# EOS-S3 register map
File version: 0.1
CPU: CM4 r0p1, selectable endian, MPU, FPU, 3 interrupt priority bits
Registers are 32-bit, read-write, reset 0x0 unless marked. A register's access mark holds for its fields unless they carry their own. Offsets are from the block's base; [hi:lo] are bit positions; {n}, {i} and the like mark numbered series.

## SPT — Simple Periodic Timer
Base 0x40005C00
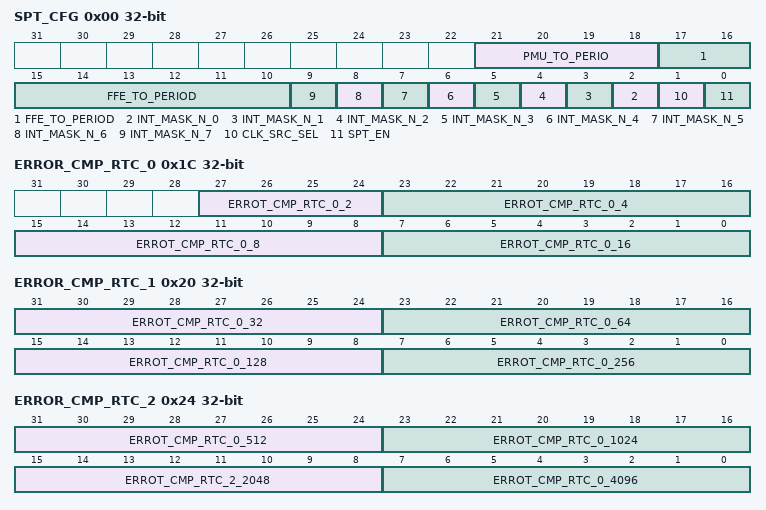
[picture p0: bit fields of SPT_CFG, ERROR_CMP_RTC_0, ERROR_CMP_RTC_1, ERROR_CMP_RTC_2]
0x00 SPT_CFG — Configuration register for the simple periodic timer
  [21:18] PMU_TO_PERIO — PMU Kick Off (Time out Period) Configuration PMU Kick Off signal will assert N cycles (value in field) before FFE kick signal asserting. NOTE : For 0x0, FFE Time out Event will be used to wake up FFE power domain.
  [17:10] FFE_TO_PERIOD — FFE Kick Off (timeout) perdiod configuration (value in registers = period, max value is 100). NOTE : If 0x0, The Event Counter will be turn off and all the Signals to PMU will be de-asserted. NOTE : If PMU_TO_PERIOD is 0x0, FFE Kick off signal will not trigger until FFE is alive.
  [n+2] INT_MASK_N_{n} (n=0..7) — Activate or deactive interrupt trigger signal {n}
    0=Unmask the interrupt; 1=Mask the interrupt
  [1] CLK_SRC_SEL — Select the clock source
    0=clock_32khz (Clock source is 32KHz); 1=clock_16khz (Clock source is 16KHz)
  [0] SPT_EN — Field to enable the timer/counter
    0=disable (Except 30 bits Timer, all the counter will be reset to 0.); 1=enable (Turn on Counter/Timer)
0x04 SLEEP_MODE — Allows blocking the PMU and FFE kickoff signal
  [0] SLEEP_MODE — If set, the PMU and FFE kick off signal will be blocked. This bit will be cleared by HW if any of non-Mask INT triggered
0x08 ERROR_CMP_40M — 40 msec increment error compensation register
  [19:0] ERROR_CMP_40M — Each 40ms period contains sub-events. For each sub-event, you can add 1ms when it triggers. Theres a sub-event every odd number, with each bit of this field corresponding to that event, so: [bit 0 = 1st ms event, bit 1 = 3rd ms event ... bit 19 = 39th ms event]
0x0C ERROR_CMP_1S_0 — 1 sec Increment Error Compensation 0 Register
  [31:0] ERROR_CMP_1S_0 — Each 1s period contains sub-events for every 40ms counted, and a subevent for the first ms counted. Each bit-pair in this field corresponds to one of those sub-events. Values of 0 or 2 in bit pairs do nothing. A value of 3 means the counter should decrease 1ms everytime the subevent is triggered, and a value of 1 means the counter should increment 1ms every time the event is triggered. [bits 1:0 = 1st 1ms event, bit 3:2 = 1st 40ms event ... 31:30 = 15th 40ms event]
0x10 ERROR_CMP_1S_1 — 1 sec Incremente Error Compensation 1 Register
  [17:0] ERROR_CMP_1S_1 — Each 1s period contains sub-events for every 40ms counted. Each bit-pair in this field corresponds to one of those sub-events. Values of 0 or 2 in bit pairs do nothing. A value of 3 means the counter should decrease 1ms everytime the sub-event is triggered, and a value of 1 means the counter should increment 1ms every time the event is triggered. Starts from the 16th 40ms event. [bits 1:0 = 16st 40ms event, bit 3:2 = 17st 40ms event ... 17:16 = 24th 40ms event]
0x14 ERROR_CMP_1S_2 — 1 sec Incremente Error Compensation 2 Register
  [23:0] ERROR_CMP_1S_2 — Each 1s period contains sub-events for every 80ms counted. Each bit-pair in this field corresponds to one of those sub-events. Values of 0 or 2 in bit pairs do nothing. A value of 3 means the counter should decrease 1ms everytime the sub-event is triggered, and a value of 1 means the counter should increment 1ms every time the event is triggered. [bits 1:0 = 1st 80ms event, bit 3:2 = 2nd 80ms event ... 23:22 = 12th 80ms event]
0x18 ERROR_CMP_1S_3 — 1 sec Incremente Error Compensation 3 Register
  [11:0] ERROR_CMP_1S_3 — Each 1s period contains sub-events for every 150ms counted. Each bit-pair in this field corresponds to one of those sub-events. Values of 0 or 2 in bit pairs do nothing. A value of 3 means the counter should decrease 1ms everytime the sub-event is triggered, and a value of 1 means the counter should increment 1ms every time the event is triggered. [bits 1:0 = 1st 150ms event, bit 3:2 = 2nd 150ms event ... 11:10 = 6th 150ms event]
0x1C ERROR_CMP_RTC_0 — 2, 4, 6, 8, 16 sec Increment Error Compensation Register
  [27:24] ERROT_CMP_RTC_0_2 — Every 2s there are 2 sub-events. Each bit pair in this field corresponds to those sub-events. Values of 0 and 2 do nothing. A value of 3 means the counter should decrement 1ms, and a value of 1 means the counter must add 1ms. [bits 25:24 1002ms event, bits 27:26 1450ms event]
  [23:16] ERROT_CMP_RTC_0_4 — Every 4s there are 4 sub-events. Each bit pair in this field corresponds to those sub-events. Values of 0 and 2 do nothing. A value of 3 means the counter should decrement 1ms, and a value of 1 means the counter must add 1ms. [bits 17:16 2002ms event, bits 19:18 2450ms event, bits 21:20 3002ms event, bits 23:22 3450ms event]
  [15:8] ERROT_CMP_RTC_0_8 — Every 8s there are 4 sub-events. Each bit pair in this field corresponds to those sub-events. Values of 0 and 2 do nothing. A value of 3 means the counter should decrement 1ms, and a value of 1 means the counter must add 1ms. [bits 9:8 4002ms event, bits 11:10 4450ms event, bits 13:12 6002ms event, bits 15:14 6450ms event]
  [7:0] ERROT_CMP_RTC_0_16 — Every 16s there are 4 sub-events. Each bit pair in this field corresponds to those sub-events. Values of 0 and 2 do nothing. A value of 3 means the counter should decrement 1ms, and a value of 1 means the counter must add 1ms. [bits 1:0 4002ms event, bits 3:2 4450ms event, bits 5:4 6002ms event, bits 7:6 6450ms event]
0x20 ERROR_CMP_RTC_1 — 32, 64, 128, 256 sec Increment Error Compensation Register
  [31:24] ERROT_CMP_RTC_0_32 — Every 32s there are 4 sub-events. Each bit pair in this field corresponds to those sub-events. Values of 0 and 2 do nothing. A value of 3 means the counter should decrement 1ms, and a value of 1 means the counter must add 1ms. [bits 25:24 16002ms event, bits 27:26 16450ms event, bits 29:28 24450 event, bits 31:30 24450 event]
  [23:16] ERROT_CMP_RTC_0_64 — Every 64s there are 4 sub-events. Each bit pair in this field corresponds to those sub-events. Values of 0 and 2 do nothing. A value of 3 means the counter should decrement 1ms, and a value of 1 means the counter must add 1ms. [bits 17:16 32002ms event, bits 19:18 32450ms event, bits 21:20 48002ms event, bits 23:22 48450ms event]
  [15:8] ERROT_CMP_RTC_0_128 — Every 128s there are 4 sub-events. Each bit pair in this field corresponds to those sub-events. Values of 0 and 2 do nothing. A value of 3 means the counter should decrement 1ms, and a value of 1 means the counter must add 1ms. [bits 9:8 64002ms event, bits 11:10 64450ms event, bits 13:12 96002ms event, bits 15:14 96450ms event]
  [7:0] ERROT_CMP_RTC_0_256 — Every 256s there are 4 sub-events. Each bit pair in this field corresponds to those sub-events. Values of 0 and 2 do nothing. A value of 3 means the counter should decrement 1ms, and a value of 1 means the counter must add 1ms. [bits 1:0 128002ms event, bits 3:2 128450ms event, bits 5:4 192002ms event, bits 7:6 192450ms event]
0x24 ERROR_CMP_RTC_2 — 512, 1024, 2048, 4096 sec Increment Error Compensation Register.
  [31:24] ERROT_CMP_RTC_0_512 — Every 512s there are 4 sub-events. Each bit pair in this field corresponds to those sub-events. Values of 0 and 2 do nothing. A value of 3 means the counter should decrement 1ms, and a value of 1 means the counter must add 1ms. [bits 25:24 256002ms event, bits 27:26 256450ms event, bits 29:28 384002 event, bits 31:30 384450 event]
  [23:16] ERROT_CMP_RTC_0_1024 — Every 1024s there are 4 sub-events. Each bit pair in this field corresponds to those sub-events. Values of 0 and 2 do nothing. A value of 3 means the counter should decrement 1ms, and a value of 1 means the counter must add 1ms. [bits 17:16 512002ms event, bits 19:18 512450ms event, bits 21:20 768002ms event, bits 23:22 768450ms event]
  [15:8] ERROT_CMP_RTC_2_2048 — Every 2048s there are 4 sub-events. Each bit pair in this field corresponds to those sub-events. Values of 0 and 2 do nothing. A value of 3 means the counter should decrement 1ms, and a value of 1 means the counter must add 1ms. [bits 9:8 1024002ms event, bits 11:10 1024450ms event, bits 13:12 1536002ms event, bits 15:14 1536450ms event]
  [7:0] ERROT_CMP_RTC_0_4096 — Every 4096s there are 4 sub-events. Each bit pair in this field corresponds to those sub-events. Values of 0 and 2 do nothing. A value of 3 means the counter should decrement 1ms, and a value of 1 means the counter must add 1ms. [bits 1:0 2048002ms event, bits 3:2 2048450ms event, bits 5:4 3072002ms event, bits 7:6 3072450ms event]
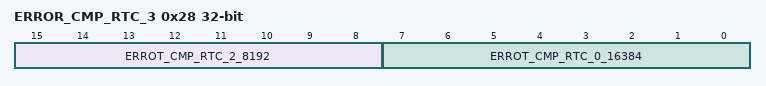
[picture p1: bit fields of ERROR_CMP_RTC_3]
0x28 ERROR_CMP_RTC_3 — 8192, 16384 sec Increment Error Compensation Register
  [15:8] ERROT_CMP_RTC_2_8192 — Every 8192s there are 4 sub-events. Each bit pair in this field corresponds to those sub-events. Values of 0 and 2 do nothing. A value of 3 means the counter should decrement 1ms, and a value of 1 means the counter must add 1ms. [bits 9:8 4096002ms event, bits 11:10 4096450ms event, bits 13:12 6144002ms event, bits 15:14 6144450ms event]
  [7:0] ERROT_CMP_RTC_0_16384 — Every 16384s there are 4 sub-events. Each bit pair in this field corresponds to those sub-events. Values of 0 and 2 do nothing. A value of 3 means the counter should decrement 1ms, and a value of 1 means the counter must add 1ms. [bits 1:0 8192002ms event, bits 3:2 8192450ms event, bits 5:4 12288002ms event, bits 7:6 12288450ms event]
0x2C UPDATE_TMR_VAL — Update the 30-Bit Timer once write. Note: Please programmed SPT_EN (0x000, bit 0) to 0 before write this register to avoid any potential issue
  [29:0] UPDATE_TIMER_VALUE
0x30 SPARE_BITS — Not documented
  [7:0] SPARE_BITS
0x34 TIMER_VALUE — Return the Value of 30-bits, in 1mS resoultion. This is the RTC value
  [29:0] TIMER_VALUE ro
0x38 EVENT_CNT_VALUE — Return the Value of the Event counter generating FFE Time out event It is an upcount counter, in 1mS resoultion.
  [7:0] EVENT_CNT_VALUE ro
0x38 MS_CNT_VALUE reset 0x40 — Return the Value of the 1mS counter which is generating the 1mS event. It is an downcount counter. Default is 0x40 (65-1). For 32KHz input, the resoultion is ~15uS. For 16KHz input, the resoultion is ~30uS
  [7:0] MS_CNT_VALUE ro
